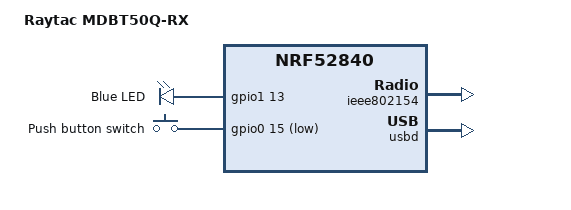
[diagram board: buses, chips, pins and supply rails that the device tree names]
/*
 * You probably need to update the old UF2 bootloader that comes with the dongle
 * to a more recent one.
 *
 * I used these instructions:
 * https://learn.adafruit.com/introducing-the-adafruit-nrf52840-feather/update-bootloader-use-uf2
 *
 * And I used this bootloader 0.9.2:
 * https://github.com/adafruit/Adafruit_nRF52_Bootloader/releases/tag/0.9.2
 *
 * Specifically this one:
 * https://github.com/adafruit/Adafruit_nRF52_Bootloader/releases/download/0.9.2/update-raytac_mdbt50q_rx_bootloader-0.9.2_nosd.uf2
 *
 * Much of this was taken from  boards/adafruit/itsybitsy_nrf52840.dts and
 * boards/seeed/xiao_ble_common.dtsi in Zephyr.
 *
 */

/dts-v1/;
#include <nordic/nrf52840_qiaa.dtsi>
#include <nordic/nrf52840_partition_uf2_sdv6.dtsi>
#include <common/nordic/nrf52840_uf2_boot_mode.dtsi>

/ {
    model = "Raytac MDBT50Q-RX";

    chosen {
        zephyr,ieee802154 = &ieee802154;
    };

    leds {
        compatible = "gpio-leds";
        led0: led_0 {
            gpios = <&gpio1 13 GPIO_ACTIVE_HIGH>;
            label = "Blue LED";
        };
    };

    buttons {
        compatible = "gpio-keys";
        button0: button_0 {
            gpios = <&gpio0 15 (GPIO_PULL_UP | GPIO_ACTIVE_LOW)>;
            label = "Push button switch";
            zephyr,code = <INPUT_KEY_0>;
        };
    };

    aliases {
        sw0 = &button0;
    };
};

&reg1 {
	regulator-initial-mode = <NRF5X_REG_MODE_DCDC>;
};

&uicr {
	gpio-as-nreset;
};

&gpio0 {
	status = "okay";
};

&gpio1 {
	status = "okay";
};

&gpiote {
	status = "okay";
};

&ieee802154 {
	status = "okay";
};

zephyr_udc0: &usbd {
	compatible = "nordic,nrf-usbd";
	status = "okay";
};

/* Add an sd_partition label for compatibility with the nosd snippet */
sd_partition: &reserved_partition_0 { };

#include <../boards/common/usb/cdc_acm_serial.dtsi>
